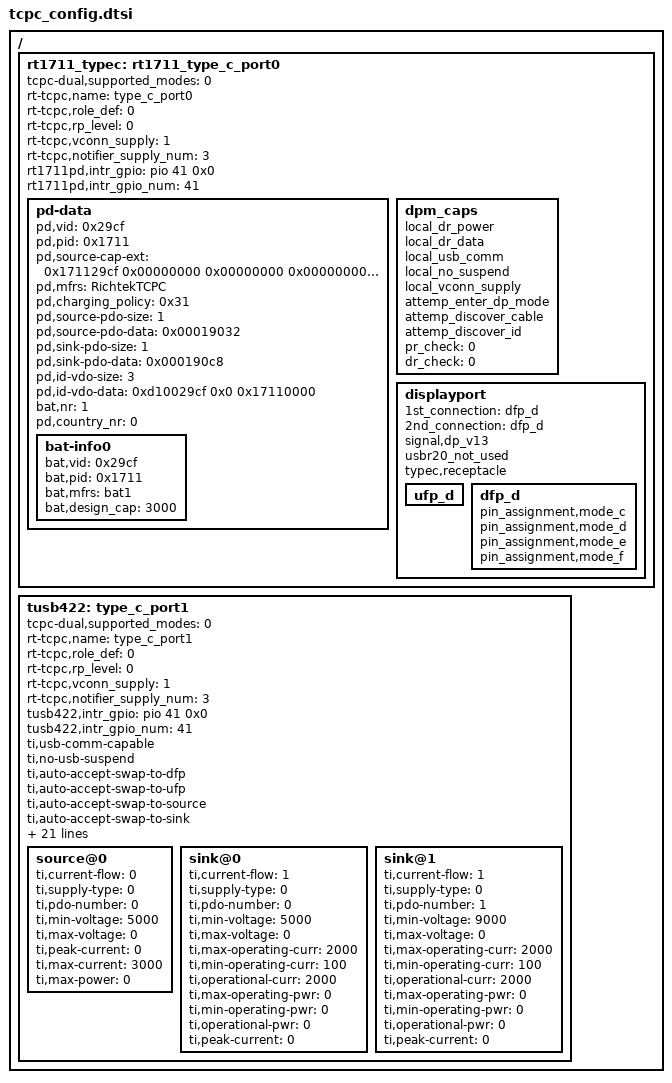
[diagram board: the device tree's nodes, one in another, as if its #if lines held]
/*
 * Copyright (c) 2017 MediaTek Inc.
 *
 * This program is free software; you can redistribute it and/or modify
 * it under the terms of the GNU General Public License version 2 as
 * published by the Free Software Foundation.
 *
 * This program is distributed in the hope that it will be useful,
 * but WITHOUT ANY WARRANTY; without even the implied warranty of
 * MERCHANTABILITY or FITNESS FOR A PARTICULAR PURPOSE.  See the
 * GNU General Public License for more details.
 */
/ {
	rt1711_typec: rt1711_type_c_port0 {
		tcpc-dual,supported_modes = <0>; /* 0: dfp/ufp, */
						 /* 1: dfp, 2: ufp */
		rt-tcpc,name = "type_c_port0"; /* tcpc_device's name */
		rt-tcpc,role_def = <0>; /* 0: SNK Only, 1: SRC Only, 2: DRP, */
					/* 3: Try.SRC, 4: Try.SNK */
		rt-tcpc,rp_level = <0>; /* 0: Default, 1: 1.5, 2: 3.0 */
		rt-tcpc,vconn_supply  = <1>;  /* 0: Never, 1: Always, */
					      /* 2: EMarkOnly, 3: StartOnly */
#if (CONFIG_MTK_GAUGE_VERSION == 30)
		rt-tcpc,notifier_supply_num = <3>;
#else
		rt-tcpc,notifier_supply_num = <2>;
#endif
		rt1711pd,intr_gpio = <&pio 41 0x0>;
		rt1711pd,intr_gpio_num = <41>;
		pd-data {
			pd,vid = <0x29cf>;
			pd,pid = <0x1711>;
			pd,source-cap-ext = <0x171129cf 0x00000000 0x00000000
					     0x00000000 0x00000000 0x02000000>;
			pd,mfrs = "RichtekTCPC";

			/*
			 *	VSAFE5V = 0, MAX_POWER = 1, CUSTOM = 2,
			 *	MAX_POWER_LV = 0x21, MAX_POWER_LVIC = 0x31
			 *	MAX_POWER_HV = 0x41, MAX_POWER_HVIC = 0x51
			 */
			pd,charging_policy= <0x31>;

			/*
			 * Fixed 5V, 500 mA <0x00019032>
			 * Fixed 5V, 1A <0x00019064>
			 * Fixed 5V, 2A <0x000190c8>
			 * Fixed 5V, 3A <0x0001912c>
			 * Fixed 9V, 500 mA <0x0002d032>
			 * Fixed 9V, 1A <0x0002d064>
			 * Fixed 9V, 2A <0x0002d0c8>
			 * Fixed 9V, 3A <0x0002d12c>
			 * Variable 5-9V, 1A <0x8642d064>
			 * Variable 5-9V, 2A <0x8642d0c8>
			 * Variable 5-9V, 3A <0x8642d12c>
			 * PPS 3V~5.9V, 3A <0xC0761E3C>
			 */
			pd,source-pdo-size = <1>;
			pd,source-pdo-data = <0x00019032>;
			pd,sink-pdo-size = <1>;
			pd,sink-pdo-data = <0x000190c8>;

			/*
			 * No DP, host + device
			 *	pd,id-vdo-size = <3>;
			 *	pd,id-vdo-data = <0xd10029cf 0x0 0x17110000>;
			 * With DP
			 *	pd,id-vdo-size = <3>;
			 *	pd,id-vdo-data = <0xd60029cf 0x0 0x17110000
			 */

			pd,id-vdo-size = <3>;
			pd,id-vdo-data = <0xd10029cf 0x0 0x17110000>;

			bat,nr = <1>;
			pd,country_nr = <0>;

			bat-info0 {
				bat,vid = <0x29cf>;
				bat,pid = <0x1711>;
				bat,mfrs = "bat1";
				bat,design_cap = <3000>;
			};

			//bat-info1 {
			//	bat,vid = <0x8abc>;
			//	bat,pid = <0x5234>;
			//	bat,mfrs = "bat2";
			//	bat,design_cap = <4000>;
			//};

			//country0 {
			//	pd,country_code = <0x5457>;
			//	pd,country_len = <2>; /* max len = 26 */
			//	pd,country_data = <0xff 0xff>;
			//};

			//country1 {
			//	pd,country_code = <0x5553>;
			//	pd,country_len = <3>; /* max len = 26 */
			//	pd,country_data = <0xf1 0xf2 0xf3>;
			//};
		};
		dpm_caps {
			local_dr_power;
			local_dr_data;
			//local_ext_power;
			local_usb_comm;
			//local_usb_suspend;
			//local_high_cap;
			//local_give_back;
			local_no_suspend;
			local_vconn_supply;

			//attemp_discover_cable_dfp;
			attemp_enter_dp_mode;
			attemp_discover_cable;
			attemp_discover_id;

			/* 0: disable, 1: prefer_snk, 2: prefer_src */
			pr_check = <0>;
			//pr_reject_as_source;
			//pr_reject_as_sink;
			//pr_check_gp_source;
			//pr_check_gp_sink;

			/* 0: disable, 1: prefer_ufp, 2: prefer_dfp */
			dr_check = <0>;
			//dr_reject_as_dfp;
			//dr_reject_as_ufp;
		};
		displayport {
			/* connection type = "both", "ufp_d", "dfp_d" */
			1st_connection = "dfp_d";
			2nd_connection = "dfp_d";
			signal,dp_v13;
			//signal,dp_gen2;
			usbr20_not_used;
			typec,receptacle;
			ufp_d {
				//pin_assignment,mode_a;
				//pin_assignment,mode_b;
				//pin_assignment,mode_c;
				//pin_assignment,mode_d;
				//pin_assignment,mode_e;
			};
			dfp_d {
				/* Only support mode C & D */
				//pin_assignment,mode_a;
				//pin_assignment,mode_b;
				pin_assignment,mode_c;
				pin_assignment,mode_d;
				pin_assignment,mode_e;
				pin_assignment,mode_f;
			};
		};
	};
	tusb422: type_c_port1 {
		tcpc-dual,supported_modes = <0>; /* 0: dfp/ufp, 1: dfp, 2: ufp */
		rt-tcpc,name = "type_c_port1"; /* tcpc_device's name */
		rt-tcpc,role_def = <0>; /* 0: SNK Only, 1: SRC Only, 2: DRP, 3: Try.SRC, 4: Try.SNK */
		rt-tcpc,rp_level = <0>; /* 0: Default, 1: 1.5, 2: 3.0 */
		rt-tcpc,vconn_supply  = <1>;  /* 0: Never, 1: Always, 2: EMarkOnly, 3: StartOnly */
#if (CONFIG_MTK_GAUGE_VERSION == 30)
		rt-tcpc,notifier_supply_num = <3>; /* the number of notifier supply */
#else
		rt-tcpc,notifier_supply_num = <2>; /* the number of notifier supply */
#endif
		//rt1711pd,intr_gpio = <&pio 110 0x0>;
		//rt1711pd,intr_gpio_num = <110>;

		tusb422,intr_gpio = <&pio 41 0x0>;
		tusb422,intr_gpio_num = <41>;

		/* Port Config */
		ti,usb-comm-capable;
		ti,no-usb-suspend;

		/* Uncomment the below tags to make them true for the driver
		 * otherwise they are false */
		/*
		ti,usb-suspend-supported;
		ti,externally-powered;
		ti,dual-role-data;
		ti,higher-capability;
		ti,giveback-flag;
		*/

		ti,auto-accept-swap-to-dfp;
		ti,auto-accept-swap-to-ufp;
		ti,auto-accept-swap-to-source;
		ti,auto-accept-swap-to-sink;
		ti,auto-accept-vconn-swap;

		ti,src-settling-time-ms = <50>;
		ti,fast-role-swap-support = <0>;
		ti,pdo-priority = <0>;
		ti,role = <1>;    /* 0 = SRC, 1 = SNK, 2 = DRP */
		ti,rp-val = <0>;  /* 0 = default, 1 = 1.5A, 2 = 3.0A */
		ti,flags = <1>;   /* 0 = none, 1 = Try.SRC, 2 = Try.SNK */

		/* Config for VDM with DisplayPort Alt-Mode Host support */
		/*ti,ufp-alt-mode-entry-timeout-enable;*/
		/*ti,multi-function-preferred;*/
		ti,id-header-vdo = <0xD5000451>; /* 0xD500xxxx = USB Host and Device communication capable and modal operation supported */
		ti,cert-stat-vdo = <0x0>;
		ti,product-vdo = <0x92610000>;
		ti,num-product-type-vdos = <0>;
		ti,product-type-vdo-1 = <0>;
		ti,product-type-vdo-2 = <0>;
		ti,product-type-vdo-3 = <0>;
		ti,num-svids = <1>;
		ti,svid-1 = <0xFF01>; /* 0xFF01 = DisplayPort. ENABLE_DP_ALT_MODE_SUPPORT must be defined in usb_pd_policy_engine.h to support this SVID */
		ti,svid-2 = <0>;
		ti,svid-3 = <0>;
		ti,mode-1 = <0x1C46>; /* 0x1C46 = DFP_D, DP_v1.3, receptacle, USB 2 signaling may be required, DFP_D pin assignment C, D, E */
		ti,mode-2 = <0>;
		ti,mode-3 = <0>;

		source@0 {
			ti,current-flow = <0>; /* 0 for source, 1 for sink */
			ti,supply-type = <0>;
			ti,pdo-number = <0>;
			ti,min-voltage = <5000>;
			ti,max-voltage = <0>;
			ti,peak-current = <0>;
			ti,max-current = <3000>;
			ti,max-power = <0>;
		};

		sink@0 {
			ti,current-flow = <1>; /* 0 for source, 1 for sink */
			ti,supply-type = <0>;
			ti,pdo-number = <0>;
			ti,min-voltage = <5000>;
			ti,max-voltage = <0>;
			ti,max-operating-curr = <2000>;
			ti,min-operating-curr = <100>;
			ti,operational-curr = <2000>;
			ti,max-operating-pwr = <0>;
			ti,min-operating-pwr = <0>;
			ti,operational-pwr = <0>;
			ti,peak-current = <0>;
		};

		sink@1 {
			ti,current-flow = <1>; /* 0 for source, 1 for sink */
			ti,supply-type = <0>;
			ti,pdo-number = <1>;
			ti,min-voltage = <9000>;
			ti,max-voltage = <0>;
			ti,max-operating-curr = <2000>;
			ti,min-operating-curr = <100>;
			ti,operational-curr = <2000>;
			ti,max-operating-pwr = <0>;
			ti,min-operating-pwr = <0>;
			ti,operational-pwr = <0>;
			ti,peak-current = <0>;
		};

	};
};

